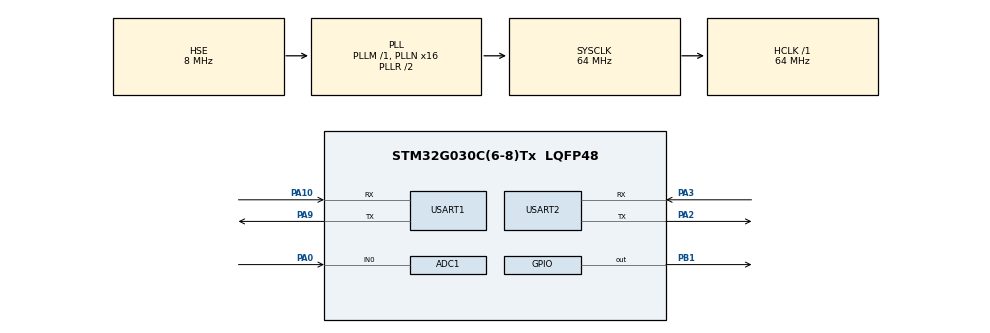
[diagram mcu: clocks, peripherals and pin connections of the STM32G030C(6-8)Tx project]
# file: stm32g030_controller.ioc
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ADC1.Channel-0\#ChannelRegularConversion=ADC_CHANNEL_0
ADC1.NbrOfConversionFlag=1
ADC1.Rank-0\#ChannelRegularConversion=1
ADC1.SamplingTime-0\#ChannelRegularConversion=ADC_SAMPLINGTIME_COMMON_1
ADC1.SelectedChannel=ADC_CHANNEL_0
ADC1.master=1
Dma.Request0=USART1_RX
Dma.Request1=USART1_TX
Dma.Request2=USART2_RX
Dma.Request3=USART2_TX
Dma.USART1_RX.0.Direction=DMA_PERIPH_TO_MEMORY
Dma.USART1_RX.0.EventEnable=DISABLE
Dma.USART1_RX.0.Instance=DMA1_Channel1
Dma.USART1_RX.0.MemDataAlignment=DMA_MDATAALIGN_BYTE
Dma.USART1_RX.0.MemInc=DMA_MINC_ENABLE
Dma.USART1_RX.0.Mode=DMA_NORMAL
Dma.USART1_RX.0.PeriphDataAlignment=DMA_PDATAALIGN_BYTE
Dma.USART1_RX.0.PeriphInc=DMA_PINC_DISABLE
Dma.USART1_RX.0.Polarity=HAL_DMAMUX_REQ_GEN_RISING
Dma.USART1_RX.0.Priority=DMA_PRIORITY_HIGH
Dma.USART1_RX.0.RequestNumber=1
Dma.USART1_RX.0.SignalID=NONE
Dma.USART1_RX.0.SyncEnable=DISABLE
Dma.USART1_RX.0.SyncPolarity=HAL_DMAMUX_SYNC_NO_EVENT
Dma.USART1_RX.0.SyncRequestNumber=1
Dma.USART1_RX.0.SyncSignalID=NONE
Dma.USART1_TX.1.Direction=DMA_MEMORY_TO_PERIPH
Dma.USART1_TX.1.EventEnable=DISABLE
Dma.USART1_TX.1.Instance=DMA1_Channel2
Dma.USART1_TX.1.MemDataAlignment=DMA_MDATAALIGN_BYTE
Dma.USART1_TX.1.MemInc=DMA_MINC_ENABLE
Dma.USART1_TX.1.Mode=DMA_NORMAL
Dma.USART1_TX.1.PeriphDataAlignment=DMA_PDATAALIGN_BYTE
Dma.USART1_TX.1.PeriphInc=DMA_PINC_DISABLE
Dma.USART1_TX.1.Polarity=HAL_DMAMUX_REQ_GEN_RISING
Dma.USART1_TX.1.Priority=DMA_PRIORITY_HIGH
Dma.USART1_TX.1.RequestNumber=1
Dma.USART1_TX.1.SignalID=NONE
Dma.USART1_TX.1.SyncEnable=DISABLE
Dma.USART1_TX.1.SyncPolarity=HAL_DMAMUX_SYNC_NO_EVENT
Dma.USART1_TX.1.SyncRequestNumber=1
Dma.USART1_TX.1.SyncSignalID=NONE
Dma.USART2_RX.2.Direction=DMA_PERIPH_TO_MEMORY
Dma.USART2_RX.2.EventEnable=DISABLE
Dma.USART2_RX.2.Instance=DMA1_Channel4
Dma.USART2_RX.2.MemDataAlignment=DMA_MDATAALIGN_BYTE
Dma.USART2_RX.2.MemInc=DMA_MINC_ENABLE
Dma.USART2_RX.2.Mode=DMA_NORMAL
Dma.USART2_RX.2.PeriphDataAlignment=DMA_PDATAALIGN_BYTE
Dma.USART2_RX.2.PeriphInc=DMA_PINC_DISABLE
Dma.USART2_RX.2.Polarity=HAL_DMAMUX_REQ_GEN_RISING
Dma.USART2_RX.2.Priority=DMA_PRIORITY_HIGH
Dma.USART2_RX.2.RequestNumber=1
Dma.USART2_RX.2.SignalID=NONE
Dma.USART2_RX.2.SyncEnable=DISABLE
Dma.USART2_RX.2.SyncPolarity=HAL_DMAMUX_SYNC_NO_EVENT
Dma.USART2_RX.2.SyncRequestNumber=1
Dma.USART2_RX.2.SyncSignalID=NONE
Dma.USART2_TX.3.Direction=DMA_MEMORY_TO_PERIPH
Dma.USART2_TX.3.EventEnable=DISABLE
Dma.USART2_TX.3.Instance=DMA1_Channel5
Dma.USART2_TX.3.MemDataAlignment=DMA_MDATAALIGN_BYTE
Dma.USART2_TX.3.MemInc=DMA_MINC_ENABLE
Dma.USART2_TX.3.Mode=DMA_NORMAL
Dma.USART2_TX.3.PeriphDataAlignment=DMA_PDATAALIGN_BYTE
Dma.USART2_TX.3.PeriphInc=DMA_PINC_DISABLE
Dma.USART2_TX.3.Polarity=HAL_DMAMUX_REQ_GEN_RISING
Dma.USART2_TX.3.Priority=DMA_PRIORITY_HIGH
Dma.USART2_TX.3.RequestNumber=1
Dma.USART2_TX.3.SignalID=NONE
Dma.USART2_TX.3.SyncEnable=DISABLE
Dma.USART2_TX.3.SyncPolarity=HAL_DMAMUX_SYNC_NO_EVENT
Dma.USART2_TX.3.SyncRequestNumber=1
Dma.USART2_TX.3.SyncSignalID=NONE
Mcu.Family=STM32G0
Mcu.Name=STM32G030C(6-8)Tx
Mcu.Package=LQFP48
NVIC.DMA1_Ch4_5_DMAMUX1_OVR_IRQn=true\:0\:0\:false\:false\:true\:false\:true\:true
NVIC.DMA1_Channel1_IRQn=true\:0\:0\:false\:false\:true\:false\:true\:true
NVIC.DMA1_Channel2_3_IRQn=true\:0\:0\:false\:false\:true\:false\:true\:true
NVIC.TIM14_IRQn=true\:3\:0\:false\:false\:true\:false\:true\:true
NVIC.TimeBase=TIM14_IRQn
NVIC.TimeBaseIP=TIM14
NVIC.USART1_IRQn=true\:0\:0\:false\:false\:true\:true\:true\:true
NVIC.USART2_IRQn=true\:0\:0\:false\:false\:true\:true\:true\:true
PA0.Mode=IN0
PA0.Signal=ADC1_IN0
PA10.Mode=Asynchronous
PA10.Signal=USART1_RX
PA13.Mode=Serial_Wire
PA13.Signal=SYS_SWDIO
PA14-BOOT0.Mode=Serial_Wire
PA14-BOOT0.Signal=SYS_SWCLK
PA2.Mode=Asynchronous
PA2.Signal=USART2_TX
PA3.Mode=Asynchronous
PA3.Signal=USART2_RX
PA9.Mode=Asynchronous
PA9.Signal=USART1_TX
PB1.GPIO_PuPd=GPIO_PULLUP
PB1.GPIO_Speed=GPIO_SPEED_FREQ_HIGH
PB1.PinState=GPIO_PIN_SET
PB1.Signal=GPIO_Output
PF0-OSC_IN\ (PF0).Mode=HSE-External-Oscillator
PF0-OSC_IN\ (PF0).Signal=RCC_OSC_IN
PF1-OSC_OUT\ (PF1).Mode=HSE-External-Oscillator
PF1-OSC_OUT\ (PF1).Signal=RCC_OSC_OUT
ProjectManager.HeapSize=0x200
ProjectManager.StackSize=0x400
ProjectManager.TargetToolchain=Makefile
RCC.ADCFreq_Value=64000000
RCC.AHBFreq_Value=64000000
RCC.CortexFreq_Value=64000000
RCC.EXTERNAL_CLOCK_VALUE=12288000
RCC.HCLKFreq_Value=64000000
RCC.HSE_VALUE=8000000
RCC.HSI_VALUE=16000000
RCC.LSE_VALUE=32768
RCC.PLLN=16
RCC.PLLSourceVirtual=RCC_PLLSOURCE_HSE
RCC.SYSCLKFreq_VALUE=64000000
RCC.SYSCLKSource=RCC_SYSCLKSOURCE_PLLCLK
RCC.VCOOutputFreq_Value=128000000
TIM17.Prescaler=64-1
USART1.VirtualMode-Asynchronous=VM_ASYNC
USART2.VirtualMode-Asynchronous=VM_ASYNC
VP_SYS_VS_tim14.Mode=TIM14
VP_TIM17_VS_ClockSourceINT.Mode=Enable_Timer
board=custom

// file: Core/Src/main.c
/* USER CODE BEGIN Header */
/**
 ******************************************************************************
 * @file           : main.c
 * @brief          : Main program body
 ******************************************************************************
 * @attention
 *
 * Copyright (c) 2022 STMicroelectronics.
 * All rights reserved.
 *
 * This software is licensed under terms that can be found in the LICENSE file
 * in the root directory of this software component.
 * If no LICENSE file comes with this software, it is provided AS-IS.
 *
 ******************************************************************************
 */
/* USER CODE END Header */
#include "main.h"
#include "adc.h"
#include "dma.h"
#include "tim.h"
#include "usart.h"
#include "gpio.h"

/* USER CODE BEGIN Includes */
#include "bsp.h"
#include "hal.h"
#include "app.h"
/* USER CODE END Includes */

void SystemClock_Config(void);

int main(void)
{

  /* MCU Configuration--------------------------------------------------------*/

  /* Reset of all peripherals, Initializes the Flash interface and the Systick. */
  HAL_Init();

  /* Configure the system clock */
  SystemClock_Config();

  /* Initialize all configured peripherals */
  MX_GPIO_Init();
  MX_DMA_Init();
  MX_ADC1_Init();
  MX_USART1_UART_Init();
  MX_USART2_UART_Init();
  MX_TIM17_Init();
  /* USER CODE BEGIN 2 */
  BSP_Layer_Init();
  HAL_Layer_Init();
  APP_Layer_Init();

  /* USER CODE END 2 */

  /* Infinite loop */
    while (1) {

    /* USER CODE BEGIN 3 */
    APP_Loop();
    }
  /* USER CODE END 3 */
}

void SystemClock_Config(void)
{
  RCC_OscInitTypeDef RCC_OscInitStruct = {0};
  RCC_ClkInitTypeDef RCC_ClkInitStruct = {0};

  /** Configure the main internal regulator output voltage
  */
  HAL_PWREx_ControlVoltageScaling(PWR_REGULATOR_VOLTAGE_SCALE1);

  /** Initializes the RCC Oscillators according to the specified parameters
  * in the RCC_OscInitTypeDef structure.
  */
  RCC_OscInitStruct.OscillatorType = RCC_OSCILLATORTYPE_HSE;
  RCC_OscInitStruct.HSEState = RCC_HSE_ON;
  RCC_OscInitStruct.PLL.PLLState = RCC_PLL_ON;
  RCC_OscInitStruct.PLL.PLLSource = RCC_PLLSOURCE_HSE;
  RCC_OscInitStruct.PLL.PLLM = RCC_PLLM_DIV1;
  RCC_OscInitStruct.PLL.PLLN = 16;
  RCC_OscInitStruct.PLL.PLLP = RCC_PLLP_DIV2;
  RCC_OscInitStruct.PLL.PLLR = RCC_PLLR_DIV2;
  if (HAL_RCC_OscConfig(&RCC_OscInitStruct) != HAL_OK)
  {
    Error_Handler();
  }

  /** Initializes the CPU, AHB and APB buses clocks
  */
  RCC_ClkInitStruct.ClockType = RCC_CLOCKTYPE_HCLK|RCC_CLOCKTYPE_SYSCLK
                              |RCC_CLOCKTYPE_PCLK1;
  RCC_ClkInitStruct.SYSCLKSource = RCC_SYSCLKSOURCE_PLLCLK;
  RCC_ClkInitStruct.AHBCLKDivider = RCC_SYSCLK_DIV1;
  RCC_ClkInitStruct.APB1CLKDivider = RCC_HCLK_DIV1;

  if (HAL_RCC_ClockConfig(&RCC_ClkInitStruct, FLASH_LATENCY_2) != HAL_OK)
  {
    Error_Handler();
  }
}

void HAL_TIM_PeriodElapsedCallback(TIM_HandleTypeDef *htim)
{
  if (htim->Instance == TIM14) {
    HAL_IncTick();
  }
}

void Error_Handler(void)
{
    __disable_irq();
    while (1) {
    }
}
